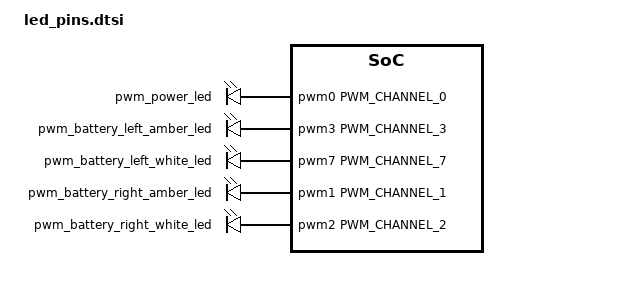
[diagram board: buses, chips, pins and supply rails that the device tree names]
/* Copyright 2026 The ChromiumOS Authors
 * Use of this source code is governed by a BSD-style license that can be
 * found in the LICENSE file.
 */

/ {
	pwm-leds {
		compatible = "pwm-leds";
		pwm_power_led: pwm_power_led {
			pwms = <&pwm0 PWM_CHANNEL_0 PWM_HZ(324) PWM_POLARITY_INVERTED>;
		};
		pwm_battery_left_amber_led: pwm_battery_left_amber_led {
			pwms = <&pwm3 PWM_CHANNEL_3 PWM_HZ(324) PWM_POLARITY_INVERTED>;
		};
		pwm_battery_left_white_led: pwm_battery_left_white_led {
			pwms = <&pwm7 PWM_CHANNEL_7 PWM_HZ(324) PWM_POLARITY_INVERTED>;
		};
		pwm_battery_right_amber_led: pwm_battery_right_amber_led {
			pwms = <&pwm1 PWM_CHANNEL_1 PWM_HZ(324) PWM_POLARITY_INVERTED>;
		};
		pwm_battery_right_white_led: pwm_battery_right_white_led {
			pwms = <&pwm2 PWM_CHANNEL_2 PWM_HZ(324) PWM_POLARITY_INVERTED>;
		};
	};

	cros-pwmleds {
		compatible = "cros-ec,pwm-leds";

		leds = <&pwm_power_led>;
		leds = <&pwm_battery_left_amber_led>;
		leds = <&pwm_battery_left_white_led>;
		leds = <&pwm_battery_right_amber_led>;
		leds = <&pwm_battery_right_white_led>;
	};
};
